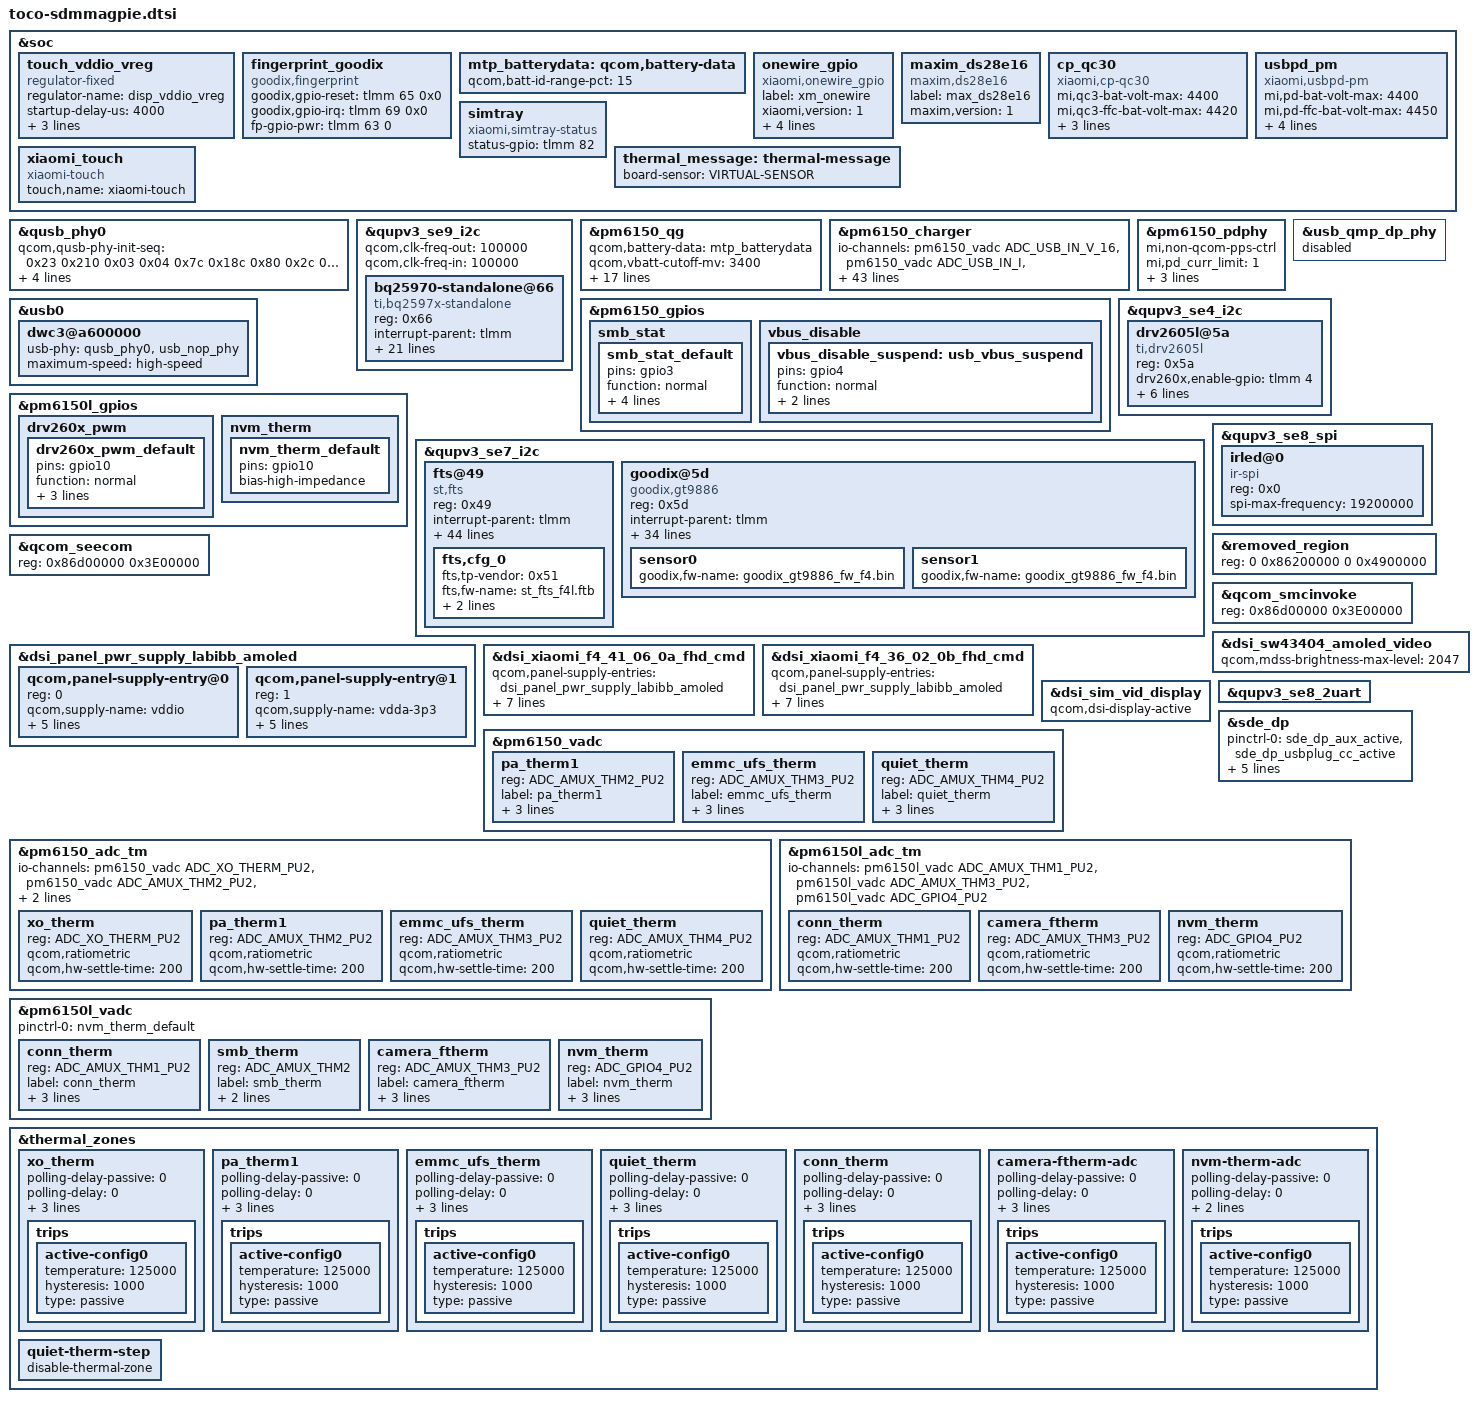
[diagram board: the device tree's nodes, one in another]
/*
this file is for attribution only of aquila
And public attribution of xiaomi platforms(like F3 and so and)
*/

#include "toco-sdmmagpie-pinctrl.dtsi"
#include "xiaomi-sdmmagpie-common.dtsi"
#include "toco-sdmmagpie-camera-sensor.dtsi"

&soc {
	touch_vddio_vreg: touch_vddio_vreg {
		compatible = "regulator-fixed";
		regulator-name = "disp_vddio_vreg";
		startup-delay-us = <4000>;
		enable-active-high;
		regulator-boot-on;
		gpio = <&tlmm 72 0>;
	};
	fingerprint_goodix {
		compatible = "goodix,fingerprint";
		goodix,gpio-reset = <&tlmm 65 0x0>;
		goodix,gpio-irq = <&tlmm 69 0x0>;
		fp-gpio-pwr = <&tlmm 63 0>;
		status = "ok";
	};

	mtp_batterydata: qcom,battery-data {
		qcom,batt-id-range-pct = <15>;
		#include "batterydata-F4L-sunwoda-5270mah.dtsi"
	};

	onewire_gpio: onewire_gpio{
		compatible = "xiaomi,onewire_gpio";
		label = "xm_onewire";
		xiaomi,version = <1>;
		xiaomi,ow_gpio = <&tlmm 94 0x00>;
		mi,onewire-gpio-cfg-addr = <0x03D5E000 0x4>;
		pinctrl-names = "onewire_active", "onewire_sleep";
		pinctrl-0 = <&onewire_gpio_active>;
		pinctrl-1 = <&onewire_gpio_sleep>;
		status = "ok";
	};

	maxim_ds28e16: maxim_ds28e16{
		compatible = "maxim,ds28e16";
		label = "max_ds28e16";
		maxim,version = <1>;
		status = "ok";
	};

	cp_qc30 {
		compatible = "xiaomi,cp-qc30";
		status = "ok";
		mi,qc3-bat-volt-max = <4400>;
		mi,qc3-ffc-bat-volt-max = <4420>;
		mi,qc3-bat-curr-max = <5400>;
		mi,qc3-bus-volt-max = <12000>;
		mi,qc3-bus-curr-max = <2100>;
	};

	usbpd_pm {
		compatible = "xiaomi,usbpd-pm";
		status = "ok";
		mi,pd-bat-volt-max = <4400>;
		mi,pd-ffc-bat-volt-max = <4450>;
		mi,pd-bat-curr-max = <6000>;
		mi,pd-bus-volt-max = <12000>;
		mi,pd-bus-curr-max = <3000>;
		mi,pd-bus-curr-compensate = <100>;
	};

	simtray {
		compatible = "xiaomi,simtray-status";
		status-gpio = <&tlmm 82 0x00>;
	};
};

&qusb_phy0 {
	qcom,qusb-phy-init-seq =
		/* <value reg_offset> */
		   <0x23 0x210 /* PWR_CTRL1 */
		    0x03 0x04  /* PLL_ANALOG_CONTROLS_TWO */
		    0x7c 0x18c /* PLL_CLOCK_INVERTERS */
		    0x80 0x2c  /* PLL_CMODE */
		    0x0a 0x184 /* PLL_LOCK_DELAY */
		    0x19 0xb4  /* PLL_DIGITAL_TIMERS_TWO */
		    0x40 0x194 /* PLL_BIAS_CONTROL_1 */
		    0x20 0x198 /* PLL_BIAS_CONTROL_2 */
		    0x21 0x214 /* PWR_CTRL2 */
		    0x08 0x220 /* IMP_CTRL1 */
		    0x58 0x224 /* IMP_CTRL2 */
		    0x07 0x240 /* TUNE1 */
		    0x29 0x244 /* TUNE2 */
		    0xca 0x248 /* TUNE3 */
		    0x07 0x24c /* TUNE4 */
		    0x03 0x250 /* TUNE5 */
		    0x30 0x23c /* CHG_CTRL2 */
		    0x22 0x210>; /* PWR_CTRL1 */
		    mi,efuse-pll-bias;
		    mi,efuse-pll-bias-seq = <1 0x20>;
		    mi,efuse-pll-bias-host;
		    mi,efuse-pll-bias-seq-host = <1 0x20>;
};

&qupv3_se9_i2c {
	status = "ok";
	qcom,clk-freq-out = <100000>;
	qcom,clk-freq-in = <100000>;

	bq25970-standalone@66 {
		compatible = "ti,bq2597x-standalone";
		reg = <0x66>;

		interrupt-parent = <&tlmm>;
		interrupts = <58 0x2002>;
		pinctrl-names = "default";
		pinctrl-0 = <&bq2597x_int_default &bq2597x_int_suspend>;

		/*ti,bq2597x,bat-ovp-disable;*/
		ti,bq2597x,bat-ovp-alarm-disable;
		ti,bq2597x,bat-ocp-disable;
		ti,bq2597x,bat-ocp-alarm-disable;
		ti,bq2597x,bat-ucp-alarm-disable;
		ti,bq2597x,bat-ucp-disable;

		/*ti,bq2597x,bus-ovp-alarm-disable;
		ti,bq2597x,bus-ocp-disable;
		ti,bq2597x,bus-ocp-alarm-disable;*/
		ti,bq2597x,bat-therm-disable;
		ti,bq2597x,bus-therm-disable;
		ti,bq2597x,die-therm-disable;

		ti,bq2597x,bat-ovp-threshold = <4480>;
		ti,bq2597x,bat-ovp-alarm-threshold = <4450>;
		//ti,bq2597x,bat-ocp-threshold = <5000>;
		//ti,bq2597x,bat-ocp-alarm-threshold = <4500>;

		ti,bq2597x,bus-ovp-threshold = <12000>;
		ti,bq2597x,bus-ovp-alarm-threshold = <11000>;
		//ti,bq2597x,bus-ocp-threshold = <2200>;
		//ti,bq2597x,bus-ocp-alarm-threshold = <2000>;
		ti,bq2597x,bus-ocp-threshold = <3500>;
		ti,bq2597x,bus-ocp-alarm-threshold = <3000>;

		//ti,bq2597x,bat-ucp-alarm-threshold = <2000>;

		ti,bq2597x,bat-therm-threshold = <0x15>;/*4.1%*/
		ti,bq2597x,bus-therm-threshold = <0x15>;/*4.1%*/
		ti,bq2597x,die-therm-threshold = <145>;

		ti,bq2597x,ac-ovp-threshold = <14>;
		//ti,bq2597x,sense-resistor-mohm = <2>;
	};
};

&pm6150_qg {
	qcom,battery-data = <&mtp_batterydata>;
	qcom,vbatt-cutoff-mv = <3400>;
	qcom,vbatt-low-mv = <3500>;
	qcom,vbatt-low-cold-mv = <3800>;
	qcom,vbatt-empty-mv = <3100>;
	qcom,vbatt-empty-cold-mv = <3000>;
	qcom,s3-entry-fifo-length = <2>;
	qcom,s3-entry-ibat-ua = <25000>;
	qcom,s3-exit-ibat-ua = <45000>;
	qcom,qg-iterm-ma = <350>;
	qcom,hold-soc-while-full;
	qcom,linearize-soc;
	qcom,cl-feedback-on;
	qcom,shutdown-soc-threshold = <10>;
	qcom,qg-ext-sns;
	mi,qg-page0-unused;
	mi,ffc-iterm-change-by-temp;
	mi,software-optimize-ffc-qg-iterm;
	qcom,shutdown-delay-enable;
};

&pm6150_charger {
	io-channels = <&pm6150_vadc ADC_USB_IN_V_16>,
		      <&pm6150_vadc ADC_USB_IN_I>,
		      <&pm6150_vadc ADC_CHG_TEMP>,
		      <&pm6150_vadc ADC_DIE_TEMP>,
		      <&pm6150l_vadc ADC_AMUX_THM1_PU2>,
		      <&pm6150_vadc ADC_SBUx>,
		      <&pm6150_vadc ADC_VPH_PWR>;
	io-channel-names = "usb_in_voltage",
			   "usb_in_current",
			   "chg_temp",
			   "die_temp",
			   "conn_temp",
			   "sbux_res",
			   "vph_voltage";
	qcom,battery-data = <&mtp_batterydata>;
	qcom,usb-icl-ua = <3000000>;
	qcom,fcc-max-ua = <5900000>;
	mi,fcc-batt-unverify-ua = <2000000>;
	qcom,fv-max-uv = <4450000>;
	qcom,auto-recharge-soc = <99>;
	qcom,chg-term-src = <1>;
	qcom,chg-term-current-ma = <(-200)>;
	qcom,sec-charger-config = <0>;

	qcom,thermal-mitigation = <5900000 5000000 4500000 4000000 3500000 3000000 2900000
				   2800000 2600000 2400000 2200000 2000000 1800000 1500000
				   1000000 500000>;
	qcom,thermal-mitigation-icl
				 = <3000000 3000000 3000000 2400000 2200000 2100000 2000000
				   2000000 2000000 1900000 1800000 1600000 1500000 1300000
				   1000000 750000>;
	qcom,thermal-mitigation-dcp
				= <1800000 1800000 1800000 1800000 1800000 1800000 1800000
				   1800000 1800000 1700000 1600000 1400000 1200000 1100000
				   1100000 1000000>;
	qcom,thermal-mitigation-qc2
				= <1500000 1500000 1500000 1500000 1450000 1400000 1350000
				   1300000 1150000 1100000 1000000 900000 850000 750000
				   650000 500000>;
	qcom,thermal-fcc-qc3-normal
				= <5900000 5000000 4500000 4000000 3500000 3000000 2900000
				   2800000 2700000 2600000 2400000 2200000 2000000 2000000
				   750000 700000>;
	qcom,thermal-fcc-qc3-cp
				= <5900000 5000000 4500000 4000000 3500000 3300000 3200000
				   3100000 3000000 2800000 2600000 2400000 2200000 2000000
				   2000000 200000>;
	qcom,thermal-mitigation-pd-base
				= <5900000 5000000 4500000 4000000 3400000 3300000 3200000
				   3100000 3000000 2800000 2600000 2400000 2200000 2000000
				   1000000 700000>;
	qcom,thermal-fcc-pps-cp
				= <5900000 5500000 5000000 4500000 4000000 3500000 3200000
				   3000000 3000000 2600000 2400000 2200000 2200000 2000000
				   1000000 700000>;
	dpdm-supply = <&qusb_phy0>;
	qcom,reg-dump-enable;
	qcom,sw-jeita-enable;
	qcom,step-charging-enable;
	qcom,distinguish-qc-class-ab;
	qcom,lpd-disable;
	qcom,usbpd-phandle = <&pm6150_pdphy>;
	mi,use-bq-pump;
	mi,support-ffc;
	mi,early-status-report;
	qcom,support-conn-therm;
	vbus-disable-gpio = <&pm6150_gpios 4 0>;
	pinctrl-names = "default";
	pinctrl-0 = <&vbus_disable_suspend>;
};

&pm6150_pdphy {
	mi,non-qcom-pps-ctrl;
	mi,pd_curr_limit = <1>;
	mi,pd_max_curr_limit = <4000000>;
	mi,limit_pd_unverified_pps_vbus = <1>;
	mi,pd_unverified_pps_max_vbus_limit = <9500000>;
};

&pm6150_gpios {
	smb_stat {
		smb_stat_default: smb_stat_default {
			pins = "gpio3";
			function = "normal";
			input-enable;
			bias-pull-up;
			qcom,pull-up-strength = <PMIC_GPIO_PULL_UP_30>;
			power-source = <0>;
		};
	};

	vbus_disable {
		vbus_disable_suspend: usb_vbus_suspend {
			pins = "gpio4";
			function = "normal";
			output-low;
			power-source = <0>;
		};
	};
};

&usb0 {
	dwc3@a600000 {
		usb-phy = <&qusb_phy0>, <&usb_nop_phy>;
		maximum-speed = "high-speed";
	};
};

&usb_qmp_dp_phy {
	status = "disabled";
};

&pm6150l_gpios {
	drv260x_pwm {
		drv260x_pwm_default: drv260x_pwm_default {
			pins = "gpio10";
			function = "normal";
			power-source = <0>;
			output-low;
			input-disable;
		};
	};
};


&qupv3_se4_i2c {
	status = "ok";
	drv2605l@5a {
		compatible = "ti,drv2605l";
		reg = <0x5a>;
		drv260x,enable-gpio = <&tlmm 4 0x00>;
		mode = <1>;
		library-sel = <6>;
		vib-rated-mv = <3200>;
		vib-overdriver-mv = <3200>;
		pinctrl-names = "default";
		pinctrl-0 = <&drv260x_pwm_default>;
		drv260x,pwm-gpio = <&pm6150l_gpios 10 0x00>;
		status = "ok";
	};
};

&qupv3_se7_i2c{
	status = "ok";
	fts@49 {
		compatible = "st,fts";
		reg = <0x49>;
		interrupt-parent = <&tlmm>;
		interrupts = <9 0x2008>;
		pinctrl-names = "pmx_ts_active", "pmx_ts_suspend";
		pinctrl-0 = <&ts_active>;
		pinctrl-1 = <&ts_int_suspend &ts_reset_suspend>;
		vdd-supply = <&touch_vddio_vreg>;
		avdd-supply = <&pm6150l_l6>;
		fts,pwr-reg-name = "avdd";
		fts,bus-reg-name = "vdd";
		fts,irq-gpio = <&tlmm 9 0x2008>;
		fts,irq-gpio-name = "fts_irq";
		fts,reset-gpio-enable;
		fts,reset-gpio = <&tlmm 8 0x00>;
		fts,reset-gpio-name = "fts_rst";
		fts,irq-flags = <0x2008>; /* IRQF_ONESHOT | IRQF_TRIGGER_LOW */
		fts,x-max = <1080>;
		fts,y-max = <2340>;
		fts,default-fw-name = "st_fts_f4l.ftb";
		fts,config-array-size = <1>;
		fts,dump-click-count;
		fts,touch-up-threshold-min = <40>;
		fts,touch-up-threshold-max = <120>;
		fts,touch-up-threshold-def = <80>;
		fts,touch-tolerance-min = <5>;
		fts,touch-tolerance-max = <35>;
		fts,touch-tolerance-def = <25>;
		/*edge filter rects in gamemode*/
		fts,cornerfilter-area-step1 = <100>;
		fts,cornerfilter-area-step2 = <170>;
		fts,cornerfilter-area-step3 = <250>;
		fts,touch-deadzone-filter-ver = <2 0 0 0 0 0 0 0
									    2 1 0 0 0 0 0 0
									    2 2 0 0 5 2339 0 0
									    2 3 1074 0 1079 2339 0 0>;
		fts,touch-deadzone-filter-hor = <2 0 0 0 1079 5 0 0
									    2 1 0 2334 1079 2339 0 0
									    2 2 0 0 5 2339 0 0
									    2 3 1074 0 1079 2339 0 0>;
		fts,touch-edgezone-filter-ver = <1 0 0 0 0 0 0 0
									    1 1 0 0 0 0 0 0
									    1 2 0 0 40 2339 0 0
									    1 3 1039 0 1079 2339 0 0>;
		fts,touch-edgezone-filter-hor = <1 0 0 0 1079 40 0 0
									    1 1 0 2299 1079 2339 0 0
									    1 2 0 0 40 2339 0 0
									    1 3 1039 0 1079 2339 0 0>;
		fts,touch-cornerzone-filter-ver = <0 0 0 0 0 0 0 0
									    0 1 0 0 0 0 0 0
									    0 2 0 2039 150 2339 0 0
									    0 3 929 2039 1079 2339 0 0>;
		fts,touch-cornerzone-filter-hor1 = <0 0 0 0 170 170 0 0
									    0 1 0 0 0 0 0 0
									    0 2 0 2169 170 2339 0 0
									    0 3 0 0 0 0 0 0>;
		fts,touch-cornerzone-filter-hor2 = <0 0 0 0 0 0 0 0
									    0 1 909 0 1079 170 0 0
									    0 2 0 0 0 0 0 0
									    0 3 909 2169 1079 2339 0 0>;
		fts,touch-idletime-min = <0>;
		fts,touch-idletime-max = <12750>;
		fts,touch-idletime-def = <12450>;
		fts,cfg_0 {
			fts,tp-vendor = <0x51>;
			fts,fw-name = "st_fts_f4l.ftb";
			fts,limit-name = "stm_fts_production_limits.csv";
			fts,clicknum-file-name = "fts+sdc";
		};
	};
	goodix@5d {
		compatible = "goodix,gt9886";
		reg = <0x5d>;
		status = "ok";
		interrupt-parent = <&tlmm>;
		interrupts = <9 0x2800>;
		vtouch-supply = <&pm6150l_l6>;
		iotouch-supply = <&touch_vddio_vreg>;
		vtouch-load = <600000>;
		pinctrl-names = "pmx_ts_active","pmx_ts_suspend";
		pinctrl-0 = <&tp_active>;
		pinctrl-1 = <&tp_int_suspend &tp_reset_suspend>;
		goodix,reset-gpio = <&tlmm 8 0x0>;
		goodix,irq-gpio = <&tlmm 9 0x2800>;
		goodix,irq-flags = <2>; /* 1:trigger rising, 2:trigger falling;*/
		goodix,panel-max-id = <10>;
		goodix,panel-max-x = <1079>;
		goodix,panel-max-y = <2339>;
		goodix,panel-max-w = <127>;
		goodix,panel-max-p = <127>;
		goodix,panel-max-fod = <127>;
	/*	goodix,panel-key-map = <158 172 217>; */ /*KEY_BACK, KEY_HOMEPAGE, KEY_SEARCH*/
		goodix,power-on-delay-us = <300000>; /*300ms*/
		goodix,power-off-delay-us = <5000>;
		goodix,cfg-name = "goodix_gt9886_cfg_f4.bin";
		normal-cfg = [
				];
	/*	goodix,swap-axis; */
	/*	goodix,pen-enable; */
	/*	goodix,key-of-pen = <331 332>; */ /*BTN_STYLUS, BTN_STYLUS2*/
		goodix,touch-deadzone-filter-ver = <2 0 0 0 0 0 0 0
									    2 1 0 0 0 0 0 0
									    2 2 0 0 5 2339 0 0
									    2 3 1074 0 1079 2339 0 0>;
		goodix,touch-deadzone-filter-hor = <2 0 0 0 1079 5 0 0
									    2 1 0 2334 1079 2339 0 0
									    2 2 0 0 5 2339 0 0
									    2 3 1074 0 1079 2339 0 0>;
		goodix,touch-edgezone-filter-ver = <1 0 0 0 0 0 0 0
									    1 1 0 0 0 0 0 0
									    1 2 0 0 40 2339 0 0
									    1 3 1039 0 1079 2339 0 0>;
		goodix,touch-edgezone-filter-hor = <1 0 0 0 1079 40 0 0
									    1 1 0 2299 1079 2339 0 0
									    1 2 0 0 40 2339 0 0
									    1 3 1039 0 1079 2339 0 0>;
		goodix,touch-cornerzone-filter-ver = <0 0 0 0 0 0 0 0
									    0 1 0 0 0 0 0 0
									    0 2 0 2039 150 2339 0 0
									    0 3 929 2039 1079 2339 0 0>;
		goodix,touch-cornerzone-filter-hor1 = <0 0 0 0 170 170 0 0
									    0 1 0 0 0 0 0 0
									    0 2 0 2169 170 2339 0 0
									    0 3 0 0 0 0 0 0>;
		goodix,touch-cornerzone-filter-hor2 = <0 0 0 0 0 0 0 0
									    0 1 909 0 1079 170 0 0
									    0 2 0 0 0 0 0 0
									    0 3 909 2169 1079 2339 0 0>;
		goodix,edge-filter-corner-size = /bits/ 16 <100 170 250>;
		sensor0 {
				goodix,fw-name = "goodix_gt9886_fw_f4.bin";
				/*goodix,x2x;*/
				/*goodix,y2y;*/
		};
		sensor1 {
				goodix,fw-name = "goodix_gt9886_fw_f4.bin";
		};
	};
};

&qupv3_se8_spi {
	status = "ok";
	irled@0 {
		compatible = "ir-spi";
		reg = <0x0>;
		status = "ok";
		spi-max-frequency = <19200000>;
	};
};

&soc {
	xiaomi_touch {
		compatible = "xiaomi-touch";
		status = "ok";
		touch,name = "xiaomi-touch";
	};
	thermal_message: thermal-message {
		board-sensor = "VIRTUAL-SENSOR";
	};
};

/* Enlarge TZ memory size to 62M */
&removed_region {
	reg = <0 0x86200000 0 0x4900000>;
};

&qcom_seecom {
	reg = <0x86d00000 0x3E00000>;
};

&qcom_smcinvoke {
	reg = <0x86d00000 0x3E00000>;
};


&dsi_panel_pwr_supply_labibb_amoled {

	qcom,panel-supply-entry@0 {
		reg = <0>;
		qcom,supply-name = "vddio";
		qcom,supply-min-voltage = <1880000>;
		qcom,supply-max-voltage = <1880000>;
		qcom,supply-enable-load = <32000>;
		qcom,supply-disable-load = <80>;
		qcom,supply-pre-off-sleep = <20>;
	};

	qcom,panel-supply-entry@1 {
		reg = <1>;
		qcom,supply-name = "vdda-3p3";
		qcom,supply-min-voltage = <3000000>;
		qcom,supply-max-voltage = <3000000>;
		qcom,supply-enable-load = <13200>;
		qcom,supply-disable-load = <80>;
		qcom,supply-pre-off-sleep = <10>;
	};
};

&dsi_xiaomi_f4_41_06_0a_fhd_cmd {
	qcom,panel-supply-entries = <&dsi_panel_pwr_supply_labibb_amoled>;
	qcom,mdss-dsi-bl-pmic-control-type = "bl_ctrl_dcs";
	qcom,mdss-dsi-bl-min-level = <2>;
	qcom,mdss-dsi-bl-max-level = <2047>;
	qcom,mdss-dsi-mode-sel-gpio-state = "single_port";
	//qcom,panel-mode-gpio = <&tlmm 7 0>;
	qcom,platform-te-gpio = <&tlmm 10 0>;
	qcom,platform-reset-gpio = <&pm6150l_gpios 9 0>;
};

&dsi_xiaomi_f4_36_02_0b_fhd_cmd {
	qcom,panel-supply-entries = <&dsi_panel_pwr_supply_labibb_amoled>;
	qcom,mdss-dsi-bl-pmic-control-type = "bl_ctrl_dcs";
	qcom,mdss-dsi-bl-min-level = <2>;
	qcom,mdss-dsi-bl-max-level = <2047>;
	qcom,mdss-dsi-mode-sel-gpio-state = "single_port";
	//qcom,panel-mode-gpio = <&tlmm 7 0>;
	qcom,platform-te-gpio = <&tlmm 10 0>;
	qcom,platform-reset-gpio = <&pm6150l_gpios 9 0>;
};

&dsi_sw43404_amoled_video {
	qcom,mdss-brightness-max-level = <2047>;
};

&dsi_sim_vid_display {
	qcom,dsi-display-active;
};

&qupv3_se8_2uart {
	status = "ok";
};

&sde_dp {
        pinctrl-names = "mdss_dp_active", "mdss_dp_sleep";
        pinctrl-0 = <&sde_dp_aux_active &sde_dp_usbplug_cc_active>;
        pinctrl-1 = <&sde_dp_aux_suspend &sde_dp_usbplug_cc_suspend>;
        qcom,aux-en-gpio = <&tlmm 42 0>;
        qcom,aux-sel-gpio = <&tlmm 33 0>;
        qcom,dp-gpio-aux-switch;
};
&pm6150_vadc {
	pa_therm1 {
		reg = <ADC_AMUX_THM2_PU2>;
		label = "pa_therm1";
		qcom,ratiometric;
		qcom,hw-settle-time = <200>;
		qcom,pre-scaling = <1 1>;
	};

	emmc_ufs_therm {
		reg = <ADC_AMUX_THM3_PU2>;
		label = "emmc_ufs_therm";
		qcom,ratiometric;
		qcom,hw-settle-time = <200>;
		qcom,pre-scaling = <1 1>;
	};

	quiet_therm {
		reg = <ADC_AMUX_THM4_PU2>;
		label = "quiet_therm";
		qcom,ratiometric;
		qcom,hw-settle-time = <200>;
		qcom,pre-scaling = <1 1>;
	};
};

&pm6150_adc_tm {
	io-channels = <&pm6150_vadc ADC_XO_THERM_PU2>,
			<&pm6150_vadc ADC_AMUX_THM2_PU2>,
			<&pm6150_vadc ADC_AMUX_THM3_PU2>,
			<&pm6150_vadc ADC_AMUX_THM4_PU2>;

	/* Channel nodes */
	xo_therm {
		reg = <ADC_XO_THERM_PU2>;
		qcom,ratiometric;
		qcom,hw-settle-time = <200>;
	};

	pa_therm1 {
		reg = <ADC_AMUX_THM2_PU2>;
		qcom,ratiometric;
		qcom,hw-settle-time = <200>;
	};

	emmc_ufs_therm {
		reg = <ADC_AMUX_THM3_PU2>;
		qcom,ratiometric;
		qcom,hw-settle-time = <200>;
	};

	quiet_therm {
		reg = <ADC_AMUX_THM4_PU2>;
		qcom,ratiometric;
		qcom,hw-settle-time = <200>;
	};
};

&pm6150l_vadc {
	pinctrl-names = "default";
	pinctrl-0 = <&nvm_therm_default>;

	conn_therm {
		reg = <ADC_AMUX_THM1_PU2>;
		label = "conn_therm";
		qcom,ratiometric;
		qcom,hw-settle-time = <200>;
		qcom,pre-scaling = <1 1>;
	};

	smb_therm {
		reg = <ADC_AMUX_THM2>;
		label = "smb_therm";
		qcom,hw-settle-time = <200>;
		qcom,pre-scaling = <1 1>;
	};

	camera_ftherm {
		reg = <ADC_AMUX_THM3_PU2>;
		label = "camera_ftherm";
		qcom,ratiometric;
		qcom,hw-settle-time = <200>;
		qcom,pre-scaling = <1 1>;
	};

	nvm_therm {
		reg = <ADC_GPIO4_PU2>;
		label = "nvm_therm";
		qcom,ratiometric;
		qcom,hw-settle-time = <200>;
		qcom,pre-scaling = <1 1>;
	};
};

&pm6150l_gpios {
	nvm_therm {
		nvm_therm_default: nvm_therm_default {
			pins = "gpio10";
			bias-high-impedance;
		};
	};
};

&pm6150l_adc_tm {
	io-channels = <&pm6150l_vadc ADC_AMUX_THM1_PU2>,
			<&pm6150l_vadc ADC_AMUX_THM3_PU2>,
			<&pm6150l_vadc ADC_GPIO4_PU2>;

	/* Channel nodes */
	conn_therm {
		reg = <ADC_AMUX_THM1_PU2>;
		qcom,ratiometric;
		qcom,hw-settle-time = <200>;
	};

	camera_ftherm {
		reg = <ADC_AMUX_THM3_PU2>;
		qcom,ratiometric;
		qcom,hw-settle-time = <200>;
	};

	nvm_therm {
		reg = <ADC_GPIO4_PU2>;
		qcom,ratiometric;
		qcom,hw-settle-time = <200>;
	};
};

&thermal_zones {

	xo_therm {
		polling-delay-passive = <0>;
		polling-delay = <0>;
		thermal-governor = "user_space";
		thermal-sensors = <&pm6150_adc_tm ADC_XO_THERM_PU2>;
		trips {
			active-config0 {
				temperature = <125000>;
				hysteresis = <1000>;
				type = "passive";
			};
		};
	};

	pa_therm1 {
		polling-delay-passive = <0>;
		polling-delay = <0>;
		thermal-governor = "user_space";
		thermal-sensors = <&pm6150_adc_tm ADC_AMUX_THM2_PU2>;
		trips {
			active-config0 {
				temperature = <125000>;
				hysteresis = <1000>;
				type = "passive";
			};
		};
	};

	emmc_ufs_therm {
		polling-delay-passive = <0>;
		polling-delay = <0>;
		thermal-governor = "user_space";
		thermal-sensors = <&pm6150_adc_tm ADC_AMUX_THM3_PU2>;
		trips {
			active-config0 {
				temperature = <125000>;
				hysteresis = <1000>;
				type = "passive";
			};
		};
	};

	quiet_therm {
		polling-delay-passive = <0>;
		polling-delay = <0>;
		thermal-governor = "user_space";
		thermal-sensors = <&pm6150_adc_tm ADC_AMUX_THM4_PU2>;
		trips {
			active-config0 {
				temperature = <125000>;
				hysteresis = <1000>;
				type = "passive";
			};
		};
	};

	conn_therm {
		polling-delay-passive = <0>;
		polling-delay = <0>;
		thermal-governor = "user_space";
		thermal-sensors = <&pm6150l_adc_tm ADC_AMUX_THM1_PU2>;
		trips {
			active-config0 {
				temperature = <125000>;
				hysteresis = <1000>;
				type = "passive";
			};
		};
	};

	camera-ftherm-adc {
		polling-delay-passive = <0>;
		polling-delay = <0>;
		thermal-governor = "user_space";
		thermal-sensors = <&pm6150l_adc_tm ADC_AMUX_THM3_PU2>;
		trips {
			active-config0 {
				temperature = <125000>;
				hysteresis = <1000>;
				type = "passive";
			};
		};
	};

	nvm-therm-adc {
		polling-delay-passive = <0>;
		polling-delay = <0>;
		thermal-governor = "user_space";
		thermal-sensors = <&pm6150l_adc_tm ADC_GPIO4_PU2>;
		trips {
			active-config0 {
				temperature = <125000>;
				hysteresis = <1000>;
				type = "passive";
			};
		};
	};

	quiet-therm-step {
		disable-thermal-zone;
	};
};
